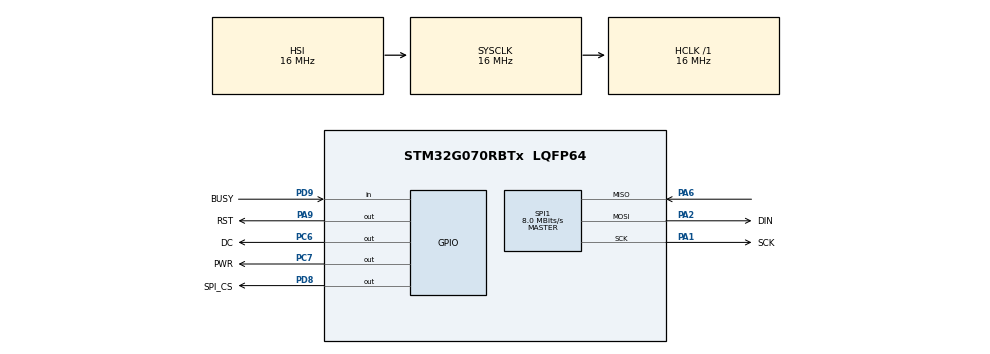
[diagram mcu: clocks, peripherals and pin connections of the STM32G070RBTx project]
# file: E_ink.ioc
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Mcu.Family=STM32G0
Mcu.Name=STM32G070RBTx
Mcu.Package=LQFP64
PA1.GPIO_Label=SCK
PA1.Mode=Full_Duplex_Master
PA1.Signal=SPI1_SCK
PA2.GPIO_Label=DIN
PA2.Mode=Full_Duplex_Master
PA2.Signal=SPI1_MOSI
PA6.Mode=Full_Duplex_Master
PA6.Signal=SPI1_MISO
PA9.GPIO_Label=RST
PA9.Signal=GPIO_Output
PC6.GPIO_Label=DC
PC6.Signal=GPIO_Output
PC7.GPIO_Label=PWR
PC7.Signal=GPIO_Output
PD8.GPIO_Label=SPI_CS
PD8.Signal=GPIO_Output
PD9.GPIO_Label=BUSY
PD9.Signal=GPIO_Input
ProjectManager.HeapSize=0x200
ProjectManager.StackSize=0x400
ProjectManager.TargetToolchain=STM32CubeIDE
RCC.AHBFreq_Value=16000000
RCC.CortexFreq_Value=16000000
RCC.EXTERNAL_CLOCK_VALUE=48000
RCC.HCLKFreq_Value=16000000
RCC.HSE_VALUE=8000000
RCC.HSI_VALUE=16000000
RCC.LSE_VALUE=32768
RCC.SYSCLKFreq_VALUE=16000000
RCC.VCOOutputFreq_Value=128000000
SPI1.CalculateBaudRate=8.0 MBits/s
SPI1.DataSize=SPI_DATASIZE_8BIT
SPI1.Direction=SPI_DIRECTION_2LINES
SPI1.Mode=SPI_MODE_MASTER
SPI1.VirtualType=VM_MASTER
board=custom

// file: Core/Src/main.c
/* USER CODE BEGIN Header */
/**
  ******************************************************************************
  * @file           : main.c
  * @brief          : Main program body
  ******************************************************************************
  * @attention
  *
  * Copyright (c) 2026 STMicroelectronics.
  * All rights reserved.
  *
  * This software is licensed under terms that can be found in the LICENSE file
  * in the root directory of this software component.
  * If no LICENSE file comes with this software, it is provided AS-IS.
  *
  ******************************************************************************
  */
/* USER CODE END Header */
#include "main.h"
#include "spi.h"
#include "gpio.h"

/* USER CODE BEGIN Includes */
#include "EPD_1in54_V2.h"
#include "cus_img.h"

/* USER CODE END Includes */

void SystemClock_Config(void);

int main(void)
{

  /* MCU Configuration--------------------------------------------------------*/

  /* Reset of all peripherals, Initializes the Flash interface and the Systick. */
  HAL_Init();

  /* Configure the system clock */
  SystemClock_Config();

  /* Initialize all configured peripherals */
  MX_GPIO_Init();
  MX_SPI1_Init();
  /* USER CODE BEGIN 2 */
 //EPD_test();

 custom_img()  ;
  /* USER CODE END 2 */

  /* Infinite loop */
  while (1)
  {

  }
}

void SystemClock_Config(void)
{
  RCC_OscInitTypeDef RCC_OscInitStruct = {0};
  RCC_ClkInitTypeDef RCC_ClkInitStruct = {0};

  /** Configure the main internal regulator output voltage
  */
  HAL_PWREx_ControlVoltageScaling(PWR_REGULATOR_VOLTAGE_SCALE1);

  /** Initializes the RCC Oscillators according to the specified parameters
  * in the RCC_OscInitTypeDef structure.
  */
  RCC_OscInitStruct.OscillatorType = RCC_OSCILLATORTYPE_HSI;
  RCC_OscInitStruct.HSIState = RCC_HSI_ON;
  RCC_OscInitStruct.HSIDiv = RCC_HSI_DIV1;
  RCC_OscInitStruct.HSICalibrationValue = RCC_HSICALIBRATION_DEFAULT;
  RCC_OscInitStruct.PLL.PLLState = RCC_PLL_NONE;
  if (HAL_RCC_OscConfig(&RCC_OscInitStruct) != HAL_OK)
  {
    Error_Handler();
  }

  /** Initializes the CPU, AHB and APB buses clocks
  */
  RCC_ClkInitStruct.ClockType = RCC_CLOCKTYPE_HCLK|RCC_CLOCKTYPE_SYSCLK
                              |RCC_CLOCKTYPE_PCLK1;
  RCC_ClkInitStruct.SYSCLKSource = RCC_SYSCLKSOURCE_HSI;
  RCC_ClkInitStruct.AHBCLKDivider = RCC_SYSCLK_DIV1;
  RCC_ClkInitStruct.APB1CLKDivider = RCC_HCLK_DIV1;

  if (HAL_RCC_ClockConfig(&RCC_ClkInitStruct, FLASH_LATENCY_0) != HAL_OK)
  {
    Error_Handler();
  }
}

void Error_Handler(void)
{
  __disable_irq();
  while (1)
  {
  }
}
